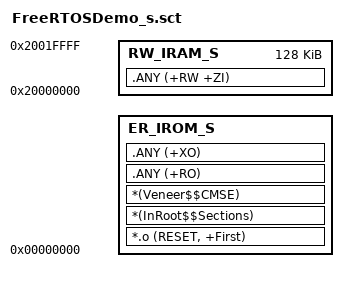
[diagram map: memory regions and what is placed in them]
; *************************************************************
; *** Scatter-Loading Description File generated by uVision ***
; *************************************************************

LR_IROM_S 0x00000000 0x00200000 ; load region size_region
{
    ER_IROM_S +0 ; load address = execution address
    {
        *.o (RESET, +First)
        *(InRoot$$Sections)
        *(Veneer$$CMSE)         ; This region is marked as Non-Secure callable in partition.h.
        .ANY (+RO)
        .ANY (+XO)
    }

    RW_IRAM_S 0x20000000 0x00020000 ; RW data
    {
        .ANY (+RW +ZI)
    }
}
